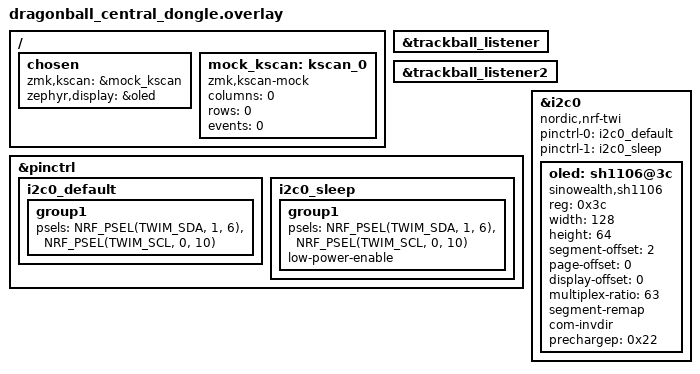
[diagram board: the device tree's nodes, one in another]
/*
 * Copyright (c) 2020 The ZMK Contributors
 *
 * SPDX-License-Identifier: MIT
 */

#include "dragonball.dtsi"
#include "split_input_common.dtsi"


/ {
    chosen {
        zmk,kscan = &mock_kscan;
        zephyr,display = &oled;
        /* CONFIG_ZMK_STUDIO build-asserts that the central has no direct
           zmk,matrix_transform chosen - the transform must only be reachable
           via zmk,physical-layout (see dragonball.dtsi). */
        /delete-property/ zmk,matrix_transform;
    };

    mock_kscan: kscan_0 {
        compatible = "zmk,kscan-mock";
        columns = <0>;
        rows = <0>;
        events = <0>;
    };
};

&trackball_listener {
    status = "okay";
};
&trackball_listener2 {
    status = "okay";
};

&pinctrl {
    i2c0_default: i2c0_default {
        group1 {
            psels = <NRF_PSEL(TWIM_SDA, 1, 6)>,
                <NRF_PSEL(TWIM_SCL, 0, 10)>;
        };
    };

    i2c0_sleep: i2c0_sleep {
        group1 {
            psels = <NRF_PSEL(TWIM_SDA, 1, 6)>,
                <NRF_PSEL(TWIM_SCL, 0, 10)>;
            low-power-enable;
        };
    };	
}; 

&i2c0 {
	status = "okay";
	compatible = "nordic,nrf-twi";
    pinctrl-0 = <&i2c0_default>;
    pinctrl-1 = <&i2c0_sleep>;
	oled: sh1106@3c {
        compatible = "sinowealth,sh1106";
        reg = <0x3c>;
        width = <128>;
        height = <64>;
        segment-offset = <2>;
        page-offset = <0>;
        display-offset = <0>;
        multiplex-ratio = <63>;
        segment-remap;
        com-invdir;
        prechargep = <0x22>;
	};
};



